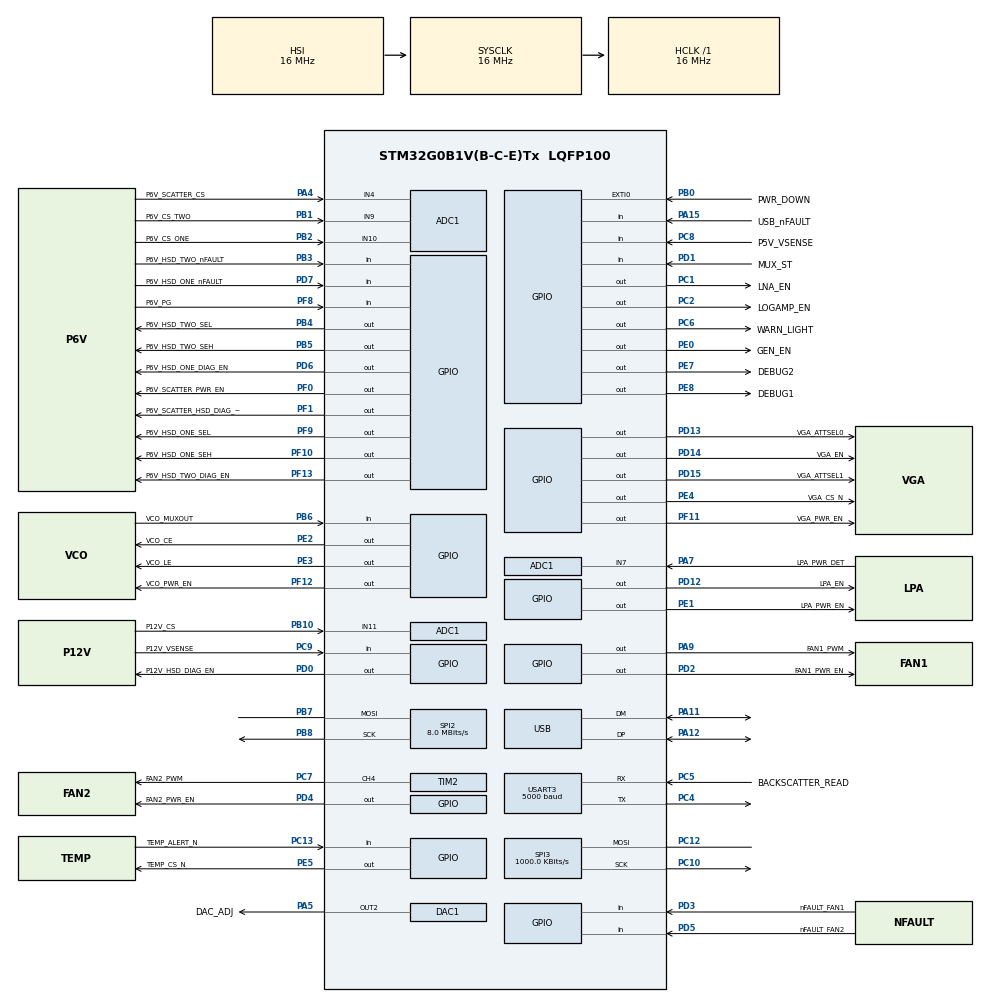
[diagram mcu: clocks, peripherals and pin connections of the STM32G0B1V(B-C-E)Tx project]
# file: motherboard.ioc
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ADC1.Channel-0\#ChannelRegularConversion=ADC_CHANNEL_4
ADC1.LowPowerAutoWait=DISABLE
ADC1.NbrOfConversionFlag=1
ADC1.OversamplingMode=ENABLE
ADC1.Rank-0\#ChannelRegularConversion=1
ADC1.Ratio=ADC_OVERSAMPLING_RATIO_16
ADC1.RightBitShift=ADC_RIGHTBITSHIFT_4
ADC1.SamplingTimeCommon1=ADC_SAMPLETIME_160CYCLES_5
ADC1.SamplingTimeCommon2=ADC_SAMPLETIME_160CYCLES_5
ADC1.SamplingTime-0\#ChannelRegularConversion=ADC_SAMPLINGTIME_COMMON_1
ADC1.SelectedChannel=ADC_CHANNEL_4|ADC_CHANNEL_7|ADC_CHANNEL_9|ADC_CHANNEL_10|ADC_CHANNEL_11
ADC1.master=1
DAC1.DAC_Channel-DAC_OUT2=DAC_CHANNEL_2
DAC1.DAC_UserTrimming-DAC_OUT2=DAC_TRIMMING_FACTORY
FREERTOS.INCLUDE_vTaskDelayUntil=1
FREERTOS.MEMORY_ALLOCATION=1
FREERTOS.Tasks01=defaultTask,0,128,StartDefaultTask,Default,NULL,Static,defaultTaskBuffer,defaultTaskControlBlock
FREERTOS.configUSE_NEWLIB_REENTRANT=1
Mcu.Family=STM32G0
Mcu.Name=STM32G0B1V(B-C-E)Tx
Mcu.Package=LQFP100
NVIC.EXTI0_1_IRQn=true\:3\:0\:false\:false\:true\:true\:true\:true\:true
NVIC.TIM1_BRK_UP_TRG_COM_IRQn=true\:3\:0\:false\:false\:true\:false\:false\:true\:true
NVIC.TimeBaseIP=TIM1
NVIC.TimeBase=TIM1_BRK_UP_TRG_COM_IRQn
NVIC.USART3_4_5_6_LPUART1_IRQn=true\:3\:0\:false\:false\:true\:true\:true\:true\:true
NVIC.USB_UCPD1_2_IRQn=true\:3\:0\:false\:false\:true\:true\:true\:true\:true
PA4.GPIO_Label=P6V_SCATTER_CS
PA4.Mode=IN4
PA4.Signal=ADC1_IN4
PA5.GPIO_Label=DAC_ADJ
PA5.Signal=COMP_DAC12_group
PA7.GPIO_Label=LPA_PWR_DET
PA7.Mode=IN7
PA7.Signal=ADC1_IN7
PA9.GPIO_Label=FAN1_PWM
PA9.Signal=GPIO_Output
PA11\ [PA9].Mode=Device
PA11\ [PA9].Signal=USB_DM
PA12\ [PA10].Mode=Device
PA12\ [PA10].Signal=USB_DP
PA15.GPIO_Label=USB_nFAULT
PA15.Signal=GPIO_Input
PB0.GPIO_Label=PWR_DOWN
PB0.GPIO_ModeDefaultEXTI=GPIO_MODE_IT_RISING
PB0.Signal=GPXTI0
PB1.GPIO_Label=P6V_CS_TWO
PB1.Mode=IN9
PB1.Signal=ADC1_IN9
PB2.GPIO_Label=P6V_CS_ONE
PB2.Mode=IN10
PB2.Signal=ADC1_IN10
PB3.GPIO_Label=P6V_HSD_TWO_nFAULT
PB3.Signal=GPIO_Input
PB4.GPIO_Label=P6V_HSD_TWO_SEL
PB4.Signal=GPIO_Output
PB5.GPIO_Label=P6V_HSD_TWO_SEH
PB5.Signal=GPIO_Output
PB6.GPIO_Label=VCO_MUXOUT
PB6.Signal=GPIO_Input
PB7.Mode=Simplex_Bidirectional_Master
PB7.Signal=SPI2_MOSI
PB8.Mode=Simplex_Bidirectional_Master
PB8.Signal=SPI2_SCK
PB10.GPIO_Label=P12V_CS
PB10.Mode=IN11
PB10.Signal=ADC1_IN11
PC1.GPIO_Label=LNA_EN
PC1.Signal=GPIO_Output
PC2.GPIO_Label=LOGAMP_EN
PC2.Signal=GPIO_Output
PC4.Mode=Asynchronous
PC4.Signal=USART3_TX
PC5.GPIO_Label=BACKSCATTER_READ
PC5.Mode=Asynchronous
PC5.Signal=USART3_RX
PC6.GPIO_Label=WARN_LIGHT
PC6.Signal=GPIO_Output
PC7.GPIO_Label=FAN2_PWM
PC7.Signal=S_TIM2_CH4
PC8.GPIO_Label=P5V_VSENSE
PC8.Signal=GPIO_Input
PC9.GPIO_Label=P12V_VSENSE
PC9.Signal=GPIO_Input
PC10.Mode=Simplex_Bidirectional_Master
PC10.Signal=SPI3_SCK
PC12.Mode=Simplex_Bidirectional_Master
PC12.Signal=SPI3_MOSI
PC13.GPIO_Label=TEMP_ALERT_N
PC13.Signal=GPIO_Input
PD0.GPIO_Label=P12V_HSD_DIAG_EN
PD0.Signal=GPIO_Output
PD1.GPIO_Label=MUX_ST
PD1.Signal=GPIO_Input
PD2.GPIO_Label=FAN1_PWR_EN
PD2.Signal=GPIO_Output
PD3.GPIO_Label=nFAULT_FAN1
PD3.Signal=GPIO_Input
PD4.GPIO_Label=FAN2_PWR_EN
PD4.Signal=GPIO_Output
PD5.GPIO_Label=nFAULT_FAN2
PD5.Signal=GPIO_Input
PD6.GPIO_Label=P6V_HSD_ONE_DIAG_EN
PD6.Signal=GPIO_Output
PD7.GPIO_Label=P6V_HSD_ONE_nFAULT
PD7.Signal=GPIO_Input
PD12.GPIO_Label=LPA_EN
PD12.Signal=GPIO_Output
PD13.GPIO_Label=VGA_ATTSEL0
PD13.Signal=GPIO_Output
PD14.GPIO_Label=VGA_EN
PD14.Signal=GPIO_Output
PD15.GPIO_Label=VGA_ATTSEL1
PD15.Signal=GPIO_Output
PE0.GPIO_Label=GEN_EN
PE0.Signal=GPIO_Output
PE1.GPIO_Label=LPA_PWR_EN
PE1.Signal=GPIO_Output
PE2.GPIO_Label=VCO_CE
PE2.Signal=GPIO_Output
PE3.GPIO_Label=VCO_LE
PE3.Signal=GPIO_Output
PE4.GPIO_Label=VGA_CS_N
PE4.GPIO_ModeDefaultOutputPP=GPIO_MODE_OUTPUT_OD
PE4.GPIO_PuPd=GPIO_NOPULL
PE4.Signal=GPIO_Output
PE5.GPIO_Label=TEMP_CS_N
PE5.GPIO_ModeDefaultOutputPP=GPIO_MODE_OUTPUT_OD
PE5.GPIO_PuPd=GPIO_NOPULL
PE5.Signal=GPIO_Output
PE7.GPIO_Label=DEBUG2
PE7.Signal=GPIO_Output
PE8.GPIO_Label=DEBUG1
PE8.Signal=GPIO_Output
PF0-OSC_IN\ (PF0).GPIO_Label=P6V_SCATTER_PWR_EN
PF0-OSC_IN\ (PF0).Signal=GPIO_Output
PF1-OSC_OUT\ (PF1).GPIO_Label=P6V_SCATTER_HSD_DIAG_EN
PF1-OSC_OUT\ (PF1).Signal=GPIO_Output
PF8.GPIO_Label=P6V_PG
PF8.Signal=GPIO_Input
PF9.GPIO_Label=P6V_HSD_ONE_SEL
PF9.Signal=GPIO_Output
PF10.GPIO_Label=P6V_HSD_ONE_SEH
PF10.Signal=GPIO_Output
PF11.GPIO_Label=VGA_PWR_EN
PF11.Signal=GPIO_Output
PF12.GPIO_Label=VCO_PWR_EN
PF12.Signal=GPIO_Output
PF13.GPIO_Label=P6V_HSD_TWO_DIAG_EN
PF13.PinState=GPIO_PIN_RESET
PF13.Signal=GPIO_Output
ProjectManager.HeapSize=0x200
ProjectManager.StackSize=0x400
ProjectManager.TargetToolchain=STM32CubeIDE
RCC.AHBFreq_Value=16000000
RCC.CortexFreq_Value=16000000
RCC.EXTERNAL_CLOCK_VALUE=48000
RCC.HCLKFreq_Value=16000000
RCC.HSE_VALUE=8000000
RCC.HSI48_VALUE=48000000
RCC.HSI_VALUE=16000000
RCC.LSE_VALUE=32768
RCC.SYSCLKFreq_VALUE=16000000
RCC.USBFreq_Value=48000000
RCC.VCOOutputFreq_Value=128000000
SH.COMP_DAC12_group.0=DAC1_OUT2,DAC_OUT2
SH.S_TIM2_CH4.0=TIM2_CH4,PWM Generation4 CH4
SPI2.CalculateBaudRate=8.0 MBits/s
SPI2.DataSize=SPI_DATASIZE_8BIT
SPI2.Direction=SPI_DIRECTION_1LINE
SPI2.Mode=SPI_MODE_MASTER
SPI2.NSSPMode=SPI_NSS_PULSE_DISABLE
SPI2.VirtualType=VM_MASTER
SPI3.BaudRatePrescaler=SPI_BAUDRATEPRESCALER_16
SPI3.CalculateBaudRate=1000.0 KBits/s
SPI3.DataSize=SPI_DATASIZE_8BIT
SPI3.Direction=SPI_DIRECTION_1LINE
SPI3.Mode=SPI_MODE_MASTER
SPI3.NSSPMode=SPI_NSS_PULSE_DISABLE
SPI3.VirtualType=VM_MASTER
TIM2.AutoReloadPreload=TIM_AUTORELOAD_PRELOAD_ENABLE
TIM2.Channel-PWM\ Generation4\ CH4=TIM_CHANNEL_4
TIM2.OCPolarity_4=TIM_OCPOLARITY_LOW
TIM2.Period=999
TIM2.Prescaler=16
USART3.BaudRate=5000
USART3.Mode=MODE_RX
USART3.RxPinLevelInvertParam=ADVFEATURE_RXINV_ENABLE
USART3.StopBits=STOPBITS_2
USART3.TxPinLevelInvertParam=ADVFEATURE_TXINV_DISABLE
USART3.VirtualMode-Asynchronous=VM_ASYNC
USB_DEVICE.CLASS_NAME_FS=CDC
USB_DEVICE.MANUFACTURER_STRING=Amber
USB_DEVICE.PRODUCT_STRING_CDC_FS=Base Station
USB_DEVICE.VirtualModeFS=Cdc_FS
USB_DEVICE.VirtualMode=Cdc
VP_FREERTOS_VS_CMSIS_V1.Mode=CMSIS_V1
VP_SYS_VS_DBSignals.Mode=DisableDeadBatterySignals
VP_SYS_VS_tim1.Mode=TIM1
VP_TIM2_VS_ClockSourceINT.Mode=Internal
VP_USB_DEVICE_VS_USB_DEVICE_CDC_FS.Mode=CDC_FS
board=custom

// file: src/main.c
/* USER CODE BEGIN Header */
/**
 ******************************************************************************
 * @file           : main.c
 * @brief          : Main program body
 ******************************************************************************
 * @attention
 *
 * Copyright (c) 2026 STMicroelectronics.
 * All rights reserved.
 *
 * This software is licensed under terms that can be found in the LICENSE file
 * in the root directory of this software component.
 * If no LICENSE file comes with this software, it is provided AS-IS.
 *
 ******************************************************************************
 */
/* USER CODE END Header */
#include "main.h"

#include "adc.h"
#include "cmsis_os.h"
#include "dac.h"
#include "gpio.h"
#include "spi.h"
#include "tim.h"
#include "usart.h"
#include "usb_device.h"

/* USER CODE BEGIN Includes */
#include "tasks.hpp"
/* USER CODE END Includes */

/* USER CODE BEGIN PV */
int pwr_down_flag = 0;
uint8_t uartReceiveCount = 0;
/* USER CODE END PV */

void SystemClock_Config(void);
void MX_FREERTOS_Init(void);

int main(void) {

    /* MCU
     * Configuration--------------------------------------------------------*/

    /* Reset of all peripherals, Initializes the Flash interface and the
     * Systick. */
    HAL_Init();

    /* Configure the system clock */
    SystemClock_Config();

    /* Initialize all configured peripherals */
    MX_GPIO_Init();
    MX_ADC1_Init();
    MX_DAC1_Init();
    MX_SPI2_Init();
    MX_SPI3_Init();
    MX_TIM2_Init();
    MX_USART3_UART_Init();
    /* USER CODE BEGIN 2 */
    MX_USB_Device_Init();
    /* USER CODE END 2 */

    /* Call init function for freertos objects (in cmsis_os2.c) */
    MX_FREERTOS_Init();

    /* Start scheduler */
    osKernelStart();

    /* We should never get here as control is now taken by the scheduler */

    /* Infinite loop */
    while (1) {

    }
}

void SystemClock_Config(void) {
    RCC_OscInitTypeDef RCC_OscInitStruct = {0};
    RCC_ClkInitTypeDef RCC_ClkInitStruct = {0};

    /** Configure the main internal regulator output voltage
     */
    HAL_PWREx_ControlVoltageScaling(PWR_REGULATOR_VOLTAGE_SCALE1);

    /** Initializes the RCC Oscillators according to the specified parameters
     * in the RCC_OscInitTypeDef structure.
     */
    RCC_OscInitStruct.OscillatorType =
        RCC_OSCILLATORTYPE_HSI | RCC_OSCILLATORTYPE_HSI48;
    RCC_OscInitStruct.HSIState = RCC_HSI_ON;
    RCC_OscInitStruct.HSI48State = RCC_HSI48_ON;
    RCC_OscInitStruct.HSIDiv = RCC_HSI_DIV1;
    RCC_OscInitStruct.HSICalibrationValue = RCC_HSICALIBRATION_DEFAULT;
    RCC_OscInitStruct.PLL.PLLState = RCC_PLL_NONE;
    if (HAL_RCC_OscConfig(&RCC_OscInitStruct) != HAL_OK) {
        Error_Handler();
    }

    /** Initializes the CPU, AHB and APB buses clocks
     */
    RCC_ClkInitStruct.ClockType =
        RCC_CLOCKTYPE_HCLK | RCC_CLOCKTYPE_SYSCLK | RCC_CLOCKTYPE_PCLK1;
    RCC_ClkInitStruct.SYSCLKSource = RCC_SYSCLKSOURCE_HSI;
    RCC_ClkInitStruct.AHBCLKDivider = RCC_SYSCLK_DIV1;
    RCC_ClkInitStruct.APB1CLKDivider = RCC_HCLK_DIV1;

    if (HAL_RCC_ClockConfig(&RCC_ClkInitStruct, FLASH_LATENCY_0) != HAL_OK) {
        Error_Handler();
    }
}

/* USER CODE BEGIN 4 */
void HAL_GPIO_EXTI_Rising_Callback(uint16_t GPIO_Pin) {
    if (GPIO_Pin == PWR_DOWN_Pin) {
        pwr_down_flag = 1;
        // your power down handling code here
        // e.g. shut off fans, save state, set a flag etc.
    }
}
/* USER CODE END 4 */

void HAL_TIM_PeriodElapsedCallback(TIM_HandleTypeDef* htim) {
    if (htim->Instance == TIM1) {
        HAL_IncTick();
    }
}

void Error_Handler(void) {
    /* USER CODE BEGIN Error_Handler_Debug */
    /* User can add his own implementation to report the HAL error return state
     */
    __disable_irq();
    while (1) {
    }
    /* USER CODE END Error_Handler_Debug */
}
#ifdef USE_FULL_ASSERT
/**
 * @brief  Reports the name of the source file and the source line number
 *         where the assert_param error has occurred.
 * @param  file: pointer to the source file name
 * @param  line: assert_param error line source number
 * @retval None
 */
void assert_failed(uint8_t* file, uint32_t line) {
    /* USER CODE BEGIN 6 */
    /* User can add his own implementation to report the file name and line
       number, ex: printf("Wrong parameters value: file %s on line %d\r\n",
       file, line) */
    /* USER CODE END 6 */
}
#endif /* USE_FULL_ASSERT */

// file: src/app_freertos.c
/* USER CODE BEGIN Header */
/**
  ******************************************************************************
  * File Name          : app_freertos.c
  * Description        : Code for freertos applications
  ******************************************************************************
  * @attention
  *
  * Copyright (c) 2026 STMicroelectronics.
  * All rights reserved.
  *
  * This software is licensed under terms that can be found in the LICENSE file
  * in the root directory of this software component.
  * If no LICENSE file comes with this software, it is provided AS-IS.
  *
  ******************************************************************************
  */
/* USER CODE END Header */

#include "FreeRTOS.h"
#include "task.h"
#include "main.h"
#include "cmsis_os.h"

osThreadId defaultTaskHandle;
uint32_t defaultTaskBuffer[ 128 ];
osStaticThreadDef_t defaultTaskControlBlock;

void StartDefaultTask(void const * argument);

void MX_FREERTOS_Init(void); /* (MISRA C 2004 rule 8.1) */

/* GetIdleTaskMemory prototype (linked to static allocation support) */
void vApplicationGetIdleTaskMemory( StaticTask_t **ppxIdleTaskTCBBuffer, StackType_t **ppxIdleTaskStackBuffer, uint32_t *pulIdleTaskStackSize );

/* USER CODE BEGIN GET_IDLE_TASK_MEMORY */
static StaticTask_t xIdleTaskTCBBuffer;
static StackType_t xIdleStack[configMINIMAL_STACK_SIZE];

void vApplicationGetIdleTaskMemory( StaticTask_t **ppxIdleTaskTCBBuffer, StackType_t **ppxIdleTaskStackBuffer, uint32_t *pulIdleTaskStackSize )
{
  *ppxIdleTaskTCBBuffer = &xIdleTaskTCBBuffer;
  *ppxIdleTaskStackBuffer = &xIdleStack[0];
  *pulIdleTaskStackSize = configMINIMAL_STACK_SIZE;
  /* place for user code */
}
/* USER CODE END GET_IDLE_TASK_MEMORY */

void MX_FREERTOS_Init(void) {

  /* Create the thread(s) */
  /* definition and creation of defaultTask */
  osThreadStaticDef(defaultTask, StartDefaultTask, osPriorityNormal, 0, 128, defaultTaskBuffer, &defaultTaskControlBlock);
  defaultTaskHandle = osThreadCreate(osThread(defaultTask), NULL);

}

void StartDefaultTask(void const * argument)
{
  /* init code for USB_Device */
  MX_USB_Device_Init();
  for(;;)
  {
    osDelay(1);
  }
}
